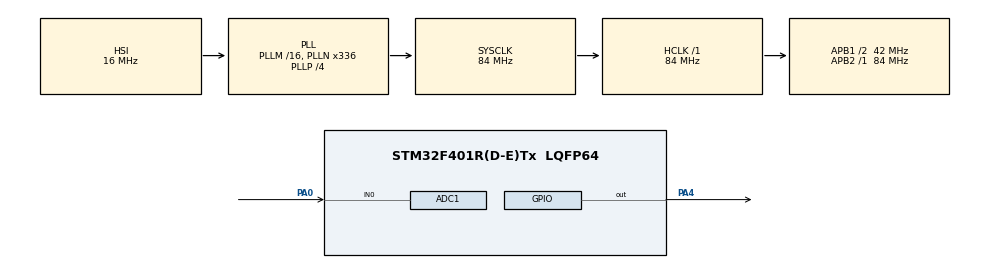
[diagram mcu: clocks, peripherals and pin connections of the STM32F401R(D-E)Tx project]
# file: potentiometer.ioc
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ADC1.Channel-0\#ChannelRegularConversion=ADC_CHANNEL_0
ADC1.NbrOfConversionFlag=1
ADC1.Rank-0\#ChannelRegularConversion=1
ADC1.SamplingTime-0\#ChannelRegularConversion=ADC_SAMPLETIME_3CYCLES
ADC1.master=1
Mcu.Family=STM32F4
Mcu.Name=STM32F401R(D-E)Tx
Mcu.Package=LQFP64
NVIC.PriorityGroup=NVIC_PRIORITYGROUP_4
PA0-WKUP.Signal=ADCx_IN0
PA4.Signal=GPIO_Output
ProjectManager.HeapSize=0x200
ProjectManager.StackSize=0x400
ProjectManager.TargetToolchain=STM32CubeIDE
RCC.48MHZClocksFreq_Value=48000000
RCC.AHBFreq_Value=84000000
RCC.APB1CLKDivider=RCC_HCLK_DIV2
RCC.APB1Freq_Value=42000000
RCC.APB1TimFreq_Value=84000000
RCC.APB2Freq_Value=84000000
RCC.APB2TimFreq_Value=84000000
RCC.CortexFreq_Value=84000000
RCC.HCLKFreq_Value=84000000
RCC.HSE_VALUE=8000000
RCC.HSI_VALUE=16000000
RCC.PLLN=336
RCC.PLLP=RCC_PLLP_DIV4
RCC.PLLQ=7
RCC.SYSCLKFreq_VALUE=84000000
RCC.SYSCLKSource=RCC_SYSCLKSOURCE_PLLCLK
RCC.VCOOutputFreq_Value=336000000
SH.ADCx_IN0.0=ADC1_IN0,IN0
board=NUCLEO-F401RE

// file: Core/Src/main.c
/* USER CODE BEGIN Header */
/**
  ******************************************************************************
  * @file           : main.c
  * @brief          : Potentiometer controls buzzer speed
  ******************************************************************************
  */
/* USER CODE END Header */

#include "main.h"
#include "stdio.h"

ADC_HandleTypeDef hadc1;

/* USER CODE BEGIN PV */
uint32_t adc_value;
uint32_t delay_time;
/* USER CODE END PV */

void SystemClock_Config(void);
static void MX_GPIO_Init(void);
static void MX_ADC1_Init(void);

int main(void)
{

  HAL_Init();

  SystemClock_Config();

  MX_GPIO_Init();
  MX_ADC1_Init();

  /* USER CODE BEGIN WHILE */
  while (1)
  {
      HAL_ADC_Start(&hadc1);

      HAL_ADC_PollForConversion(&hadc1, HAL_MAX_DELAY);

      adc_value = HAL_ADC_GetValue(&hadc1);

      HAL_ADC_Stop(&hadc1);

      delay_time = adc_value / 20;

      HAL_GPIO_WritePin(GPIOA, GPIO_PIN_4, GPIO_PIN_SET);
      HAL_Delay(delay_time);

      HAL_GPIO_WritePin(GPIOA, GPIO_PIN_4, GPIO_PIN_RESET);
      HAL_Delay(delay_time);
  }
  /* USER CODE END WHILE */

}

void SystemClock_Config(void)
{
  RCC_OscInitTypeDef RCC_OscInitStruct = {0};
  RCC_ClkInitTypeDef RCC_ClkInitStruct = {0};

  __HAL_RCC_PWR_CLK_ENABLE();
  __HAL_PWR_VOLTAGESCALING_CONFIG(PWR_REGULATOR_VOLTAGE_SCALE2);

  RCC_OscInitStruct.OscillatorType = RCC_OSCILLATORTYPE_HSI;
  RCC_OscInitStruct.HSIState = RCC_HSI_ON;
  RCC_OscInitStruct.HSICalibrationValue = RCC_HSICALIBRATION_DEFAULT;

  RCC_OscInitStruct.PLL.PLLState = RCC_PLL_ON;
  RCC_OscInitStruct.PLL.PLLSource = RCC_PLLSOURCE_HSI;

  RCC_OscInitStruct.PLL.PLLM = 16;
  RCC_OscInitStruct.PLL.PLLN = 336;
  RCC_OscInitStruct.PLL.PLLP = RCC_PLLP_DIV4;
  RCC_OscInitStruct.PLL.PLLQ = 7;

  if (HAL_RCC_OscConfig(&RCC_OscInitStruct) != HAL_OK)
  {
    Error_Handler();
  }

  RCC_ClkInitStruct.ClockType =
  RCC_CLOCKTYPE_HCLK|
  RCC_CLOCKTYPE_SYSCLK|
  RCC_CLOCKTYPE_PCLK1|
  RCC_CLOCKTYPE_PCLK2;

  RCC_ClkInitStruct.SYSCLKSource = RCC_SYSCLKSOURCE_PLLCLK;

  RCC_ClkInitStruct.AHBCLKDivider = RCC_SYSCLK_DIV1;

  RCC_ClkInitStruct.APB1CLKDivider = RCC_HCLK_DIV2;

  RCC_ClkInitStruct.APB2CLKDivider = RCC_HCLK_DIV1;

  if (HAL_RCC_ClockConfig(&RCC_ClkInitStruct, FLASH_LATENCY_2) != HAL_OK)
  {
    Error_Handler();
  }
}

static void MX_ADC1_Init(void)
{

  ADC_ChannelConfTypeDef sConfig = {0};

  hadc1.Instance = ADC1;

  hadc1.Init.ClockPrescaler = ADC_CLOCK_SYNC_PCLK_DIV4;

  hadc1.Init.Resolution = ADC_RESOLUTION_12B;

  hadc1.Init.ScanConvMode = DISABLE;

  hadc1.Init.ContinuousConvMode = DISABLE;

  hadc1.Init.DiscontinuousConvMode = DISABLE;

  hadc1.Init.ExternalTrigConvEdge = ADC_EXTERNALTRIGCONVEDGE_NONE;

  hadc1.Init.ExternalTrigConv = ADC_SOFTWARE_START;

  hadc1.Init.DataAlign = ADC_DATAALIGN_RIGHT;

  hadc1.Init.NbrOfConversion = 1;

  hadc1.Init.DMAContinuousRequests = DISABLE;

  hadc1.Init.EOCSelection = ADC_EOC_SINGLE_CONV;

  if (HAL_ADC_Init(&hadc1) != HAL_OK)
  {
    Error_Handler();
  }

  sConfig.Channel = ADC_CHANNEL_0;

  sConfig.Rank = 1;

  sConfig.SamplingTime = ADC_SAMPLETIME_3CYCLES;

  if (HAL_ADC_ConfigChannel(&hadc1, &sConfig) != HAL_OK)
  {
    Error_Handler();
  }

}

static void MX_GPIO_Init(void)
{
  GPIO_InitTypeDef GPIO_InitStruct = {0};

  __HAL_RCC_GPIOA_CLK_ENABLE();

  HAL_GPIO_WritePin(GPIOA, GPIO_PIN_4, GPIO_PIN_RESET);

  GPIO_InitStruct.Pin = GPIO_PIN_4;

  GPIO_InitStruct.Mode = GPIO_MODE_OUTPUT_PP;

  GPIO_InitStruct.Pull = GPIO_NOPULL;

  GPIO_InitStruct.Speed = GPIO_SPEED_FREQ_LOW;

  HAL_GPIO_Init(GPIOA, &GPIO_InitStruct);
}

/**
  * @brief Error Handler
  */
void Error_Handler(void)
{
  __disable_irq();
  while (1)
  {
  }
}
